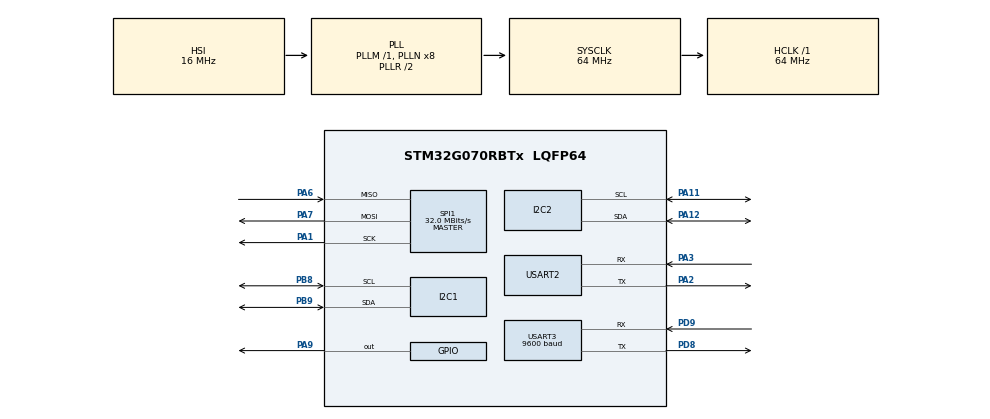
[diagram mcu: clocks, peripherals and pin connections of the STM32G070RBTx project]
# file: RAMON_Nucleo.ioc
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Dma.Request0=USART3_RX
Dma.USART3_RX.0.Direction=DMA_PERIPH_TO_MEMORY
Dma.USART3_RX.0.EventEnable=DISABLE
Dma.USART3_RX.0.Instance=DMA1_Channel1
Dma.USART3_RX.0.MemDataAlignment=DMA_MDATAALIGN_BYTE
Dma.USART3_RX.0.MemInc=DMA_MINC_ENABLE
Dma.USART3_RX.0.Mode=DMA_CIRCULAR
Dma.USART3_RX.0.PeriphDataAlignment=DMA_PDATAALIGN_BYTE
Dma.USART3_RX.0.PeriphInc=DMA_PINC_DISABLE
Dma.USART3_RX.0.Polarity=HAL_DMAMUX_REQ_GEN_RISING
Dma.USART3_RX.0.Priority=DMA_PRIORITY_LOW
Dma.USART3_RX.0.RequestNumber=1
Dma.USART3_RX.0.SignalID=NONE
Dma.USART3_RX.0.SyncEnable=DISABLE
Dma.USART3_RX.0.SyncPolarity=HAL_DMAMUX_SYNC_NO_EVENT
Dma.USART3_RX.0.SyncRequestNumber=1
Dma.USART3_RX.0.SyncSignalID=NONE
FATFS._MAX_SS=4096
FATFS._USE_LFN=1
I2C1.Timing=0x10707DBC
I2C2.Timing=0x10707DBC
Mcu.Family=STM32G0
Mcu.Name=STM32G070RBTx
Mcu.Package=LQFP64
NVIC.DMA1_Channel1_IRQn=true\:0\:0\:false\:false\:true\:false\:true\:true
PA1.Mode=Full_Duplex_Master
PA1.Signal=SPI1_SCK
PA11\ [PA9].Mode=I2C
PA11\ [PA9].Signal=I2C2_SCL
PA12\ [PA10].Mode=I2C
PA12\ [PA10].Signal=I2C2_SDA
PA13.GPIO_Label=TMS
PA13.Mode=Serial_Wire
PA13.Signal=SYS_SWDIO
PA14-BOOT0.GPIO_Label=TCK
PA14-BOOT0.Mode=Serial_Wire
PA14-BOOT0.Signal=SYS_SWCLK
PA2.GPIO_PuPd=GPIO_PULLUP
PA2.Mode=Asynchronous
PA2.Signal=USART2_TX
PA3.GPIO_PuPd=GPIO_PULLUP
PA3.Mode=Asynchronous
PA3.Signal=USART2_RX
PA6.Mode=Full_Duplex_Master
PA6.Signal=SPI1_MISO
PA7.Mode=Full_Duplex_Master
PA7.Signal=SPI1_MOSI
PA9.Signal=GPIO_Output
PB8.Mode=I2C
PB8.Signal=I2C1_SCL
PB9.Mode=I2C
PB9.Signal=I2C1_SDA
PC13.Mode=SYS_WakeUp1
PC13.Signal=SYS_WKUP2
PC14-OSC32_IN\ (PC14).Mode=LSE-External-Oscillator
PC14-OSC32_IN\ (PC14).Signal=RCC_OSC32_IN
PC15-OSC32_OUT\ (PC15).Mode=LSE-External-Oscillator
PC15-OSC32_OUT\ (PC15).Signal=RCC_OSC32_OUT
PD8.Mode=Asynchronous
PD8.Signal=USART3_TX
PD9.Mode=Asynchronous
PD9.Signal=USART3_RX
PF0-OSC_IN\ (PF0).GPIO_Label=MCO
PF0-OSC_IN\ (PF0).Mode=HSE-External-Oscillator
PF0-OSC_IN\ (PF0).Signal=RCC_OSC_IN
PF1-OSC_OUT\ (PF1).Mode=HSE-External-Oscillator
PF1-OSC_OUT\ (PF1).Signal=RCC_OSC_OUT
ProjectManager.HeapSize=0x200
ProjectManager.StackSize=0x400
ProjectManager.TargetToolchain=STM32CubeIDE
RCC.ADCFreq_Value=64000000
RCC.AHBFreq_Value=64000000
RCC.CortexFreq_Value=64000000
RCC.EXTERNAL_CLOCK_VALUE=12288000
RCC.HCLKFreq_Value=64000000
RCC.HSE_VALUE=8000000
RCC.HSI_VALUE=16000000
RCC.SYSCLKFreq_VALUE=64000000
RCC.SYSCLKSource=RCC_SYSCLKSOURCE_PLLCLK
RCC.VCOOutputFreq_Value=128000000
SPI1.CalculateBaudRate=32.0 MBits/s
SPI1.Direction=SPI_DIRECTION_2LINES
SPI1.Mode=SPI_MODE_MASTER
SPI1.VirtualType=VM_MASTER
USART2.VirtualMode-Asynchronous=VM_ASYNC
USART2.WordLength=WORDLENGTH_8B
USART3.BaudRate=9600
USART3.VirtualMode-Asynchronous=VM_ASYNC
VP_FATFS_VS_Generic.Mode=User_defined
VP_SYS_VS_DBSignals.Mode=DisableDeadBatterySignals
board=NUCLEO-G070RB

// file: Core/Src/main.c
/* USER CODE BEGIN Header */
/**
  ******************************************************************************
  * @file           : main.c
  * @brief          : Main program body
  ******************************************************************************
  * @attention
  *
  * Copyright (c) 2024 STMicroelectronics.
  * All rights reserved.
  *
  * This software is licensed under terms that can be found in the LICENSE file
  * in the root directory of this software component.
  * If no LICENSE file comes with this software, it is provided AS-IS.
  *
  ******************************************************************************
  */
/* USER CODE END Header */
#include "main.h"
#include "app_fatfs.h"

/* USER CODE BEGIN PTD */
#define USE_PSEUDO_SENSORS
/* USER CODE END PTD */

/* USER CODE BEGIN PD */
/*  SPI_HandleTypeDef hspi1;
                            FATFS fs;
                            FATFS *pfs;
                            FIL fil;
                            FRESULT fres;
                            DWORD fre_clust;
                            uint32_t totalSpace, freeSpace;
                            char buffer[100];
                            */
/* USER CODE END PD */

I2C_HandleTypeDef hi2c1;
I2C_HandleTypeDef hi2c2;

SPI_HandleTypeDef hspi1;

UART_HandleTypeDef huart2;
UART_HandleTypeDef huart3;
DMA_HandleTypeDef hdma_usart3_rx;

/* USER CODE BEGIN PV */

uint8_t rx_indx;
uint8_t rx_data[100];
uint8_t rx_buffer[100];
uint8_t transfer_cplt;

/* USER CODE END PV */

void SystemClock_Config(void);
static void MX_GPIO_Init(void);
static void MX_DMA_Init(void);
static void MX_USART2_UART_Init(void);
static void MX_I2C1_Init(void);
static void MX_I2C2_Init(void);
static void MX_SPI1_Init(void);
static void MX_USART3_UART_Init(void);

int main(void)
{

  /* MCU Configuration--------------------------------------------------------*/

  /* Reset of all peripherals, Initializes the Flash interface and the Systick. */
  HAL_Init();

  /* Configure the system clock */
  SystemClock_Config();

  /* Initialize all configured peripherals */
  MX_GPIO_Init();
  MX_DMA_Init();
  MX_USART2_UART_Init();
  if (MX_FATFS_Init() != APP_OK) {
    Error_Handler();
  }
  MX_I2C1_Init();
  MX_I2C2_Init();
  MX_SPI1_Init();
  MX_USART3_UART_Init();
  /* USER CODE BEGIN 2 */
  Start_UART_Reception(&huart2);
  if (PseudoSensor_Init(&huart2) != HAL_OK) {
      Error_Handler();
  }
  FlightSoftware_Init(&hi2c1, &hi2c2, &huart2);

  Debug_Print("Initialization complete. Starting main loop.\r\n");

  FlightSoftware_Run();
  /* USER CODE END 2 */

  /* Infinite loop */

}

void SystemClock_Config(void)
{
  RCC_OscInitTypeDef RCC_OscInitStruct = {0};
  RCC_ClkInitTypeDef RCC_ClkInitStruct = {0};

  /** Configure the main internal regulator output voltage
  */
  HAL_PWREx_ControlVoltageScaling(PWR_REGULATOR_VOLTAGE_SCALE1);

  /** Initializes the RCC Oscillators according to the specified parameters
  * in the RCC_OscInitTypeDef structure.
  */
  RCC_OscInitStruct.OscillatorType = RCC_OSCILLATORTYPE_HSI;
  RCC_OscInitStruct.HSIState = RCC_HSI_ON;
  RCC_OscInitStruct.HSIDiv = RCC_HSI_DIV1;
  RCC_OscInitStruct.HSICalibrationValue = RCC_HSICALIBRATION_DEFAULT;
  RCC_OscInitStruct.PLL.PLLState = RCC_PLL_ON;
  RCC_OscInitStruct.PLL.PLLSource = RCC_PLLSOURCE_HSI;
  RCC_OscInitStruct.PLL.PLLM = RCC_PLLM_DIV1;
  RCC_OscInitStruct.PLL.PLLN = 8;
  RCC_OscInitStruct.PLL.PLLP = RCC_PLLP_DIV2;
  RCC_OscInitStruct.PLL.PLLR = RCC_PLLR_DIV2;
  if (HAL_RCC_OscConfig(&RCC_OscInitStruct) != HAL_OK)
  {
    Error_Handler();
  }

  /** Initializes the CPU, AHB and APB buses clocks
  */
  RCC_ClkInitStruct.ClockType = RCC_CLOCKTYPE_HCLK|RCC_CLOCKTYPE_SYSCLK
                              |RCC_CLOCKTYPE_PCLK1;
  RCC_ClkInitStruct.SYSCLKSource = RCC_SYSCLKSOURCE_PLLCLK;
  RCC_ClkInitStruct.AHBCLKDivider = RCC_SYSCLK_DIV1;
  RCC_ClkInitStruct.APB1CLKDivider = RCC_HCLK_DIV1;

  if (HAL_RCC_ClockConfig(&RCC_ClkInitStruct, FLASH_LATENCY_2) != HAL_OK)
  {
    Error_Handler();
  }
}

static void MX_I2C1_Init(void)
{

  hi2c1.Instance = I2C1;
  hi2c1.Init.Timing = 0x10707DBC;
  hi2c1.Init.OwnAddress1 = 0;
  hi2c1.Init.AddressingMode = I2C_ADDRESSINGMODE_7BIT;
  hi2c1.Init.DualAddressMode = I2C_DUALADDRESS_DISABLE;
  hi2c1.Init.OwnAddress2 = 0;
  hi2c1.Init.OwnAddress2Masks = I2C_OA2_NOMASK;
  hi2c1.Init.GeneralCallMode = I2C_GENERALCALL_DISABLE;
  hi2c1.Init.NoStretchMode = I2C_NOSTRETCH_DISABLE;
  if (HAL_I2C_Init(&hi2c1) != HAL_OK)
  {
    Error_Handler();
  }

  /** Configure Analogue filter
  */
  if (HAL_I2CEx_ConfigAnalogFilter(&hi2c1, I2C_ANALOGFILTER_ENABLE) != HAL_OK)
  {
    Error_Handler();
  }

  /** Configure Digital filter
  */
  if (HAL_I2CEx_ConfigDigitalFilter(&hi2c1, 0) != HAL_OK)
  {
    Error_Handler();
  }

}

static void MX_I2C2_Init(void)
{

  hi2c2.Instance = I2C2;
  hi2c2.Init.Timing = 0x10707DBC;
  hi2c2.Init.OwnAddress1 = 0;
  hi2c2.Init.AddressingMode = I2C_ADDRESSINGMODE_7BIT;
  hi2c2.Init.DualAddressMode = I2C_DUALADDRESS_DISABLE;
  hi2c2.Init.OwnAddress2 = 0;
  hi2c2.Init.OwnAddress2Masks = I2C_OA2_NOMASK;
  hi2c2.Init.GeneralCallMode = I2C_GENERALCALL_DISABLE;
  hi2c2.Init.NoStretchMode = I2C_NOSTRETCH_DISABLE;
  if (HAL_I2C_Init(&hi2c2) != HAL_OK)
  {
    Error_Handler();
  }

  /** Configure Analogue filter
  */
  if (HAL_I2CEx_ConfigAnalogFilter(&hi2c2, I2C_ANALOGFILTER_ENABLE) != HAL_OK)
  {
    Error_Handler();
  }

  /** Configure Digital filter
  */
  if (HAL_I2CEx_ConfigDigitalFilter(&hi2c2, 0) != HAL_OK)
  {
    Error_Handler();
  }

}

static void MX_SPI1_Init(void)
{

  /* SPI1 parameter configuration*/
  hspi1.Instance = SPI1;
  hspi1.Init.Mode = SPI_MODE_MASTER;
  hspi1.Init.Direction = SPI_DIRECTION_2LINES;
  hspi1.Init.DataSize = SPI_DATASIZE_4BIT;
  hspi1.Init.CLKPolarity = SPI_POLARITY_LOW;
  hspi1.Init.CLKPhase = SPI_PHASE_1EDGE;
  hspi1.Init.NSS = SPI_NSS_SOFT;
  hspi1.Init.BaudRatePrescaler = SPI_BAUDRATEPRESCALER_2;
  hspi1.Init.FirstBit = SPI_FIRSTBIT_MSB;
  hspi1.Init.TIMode = SPI_TIMODE_DISABLE;
  hspi1.Init.CRCCalculation = SPI_CRCCALCULATION_DISABLE;
  hspi1.Init.CRCPolynomial = 7;
  hspi1.Init.CRCLength = SPI_CRC_LENGTH_DATASIZE;
  hspi1.Init.NSSPMode = SPI_NSS_PULSE_ENABLE;
  if (HAL_SPI_Init(&hspi1) != HAL_OK)
  {
    Error_Handler();
  }

}

static void MX_USART2_UART_Init(void)
{

  huart2.Instance = USART2;
  huart2.Init.BaudRate = 115200;
  huart2.Init.WordLength = UART_WORDLENGTH_8B;
  huart2.Init.StopBits = UART_STOPBITS_1;
  huart2.Init.Parity = UART_PARITY_NONE;
  huart2.Init.Mode = UART_MODE_TX_RX;
  huart2.Init.HwFlowCtl = UART_HWCONTROL_NONE;
  huart2.Init.OverSampling = UART_OVERSAMPLING_16;
  huart2.Init.OneBitSampling = UART_ONE_BIT_SAMPLE_DISABLE;
  huart2.Init.ClockPrescaler = UART_PRESCALER_DIV1;
  huart2.AdvancedInit.AdvFeatureInit = UART_ADVFEATURE_NO_INIT;
  if (HAL_UART_Init(&huart2) != HAL_OK)
  {
    Error_Handler();
  }
  if (HAL_UARTEx_SetTxFifoThreshold(&huart2, UART_TXFIFO_THRESHOLD_1_8) != HAL_OK)
  {
    Error_Handler();
  }
  if (HAL_UARTEx_SetRxFifoThreshold(&huart2, UART_RXFIFO_THRESHOLD_1_8) != HAL_OK)
  {
    Error_Handler();
  }
  if (HAL_UARTEx_DisableFifoMode(&huart2) != HAL_OK)
  {
    Error_Handler();
  }

}

static void MX_USART3_UART_Init(void)
{

  huart3.Instance = USART3;
  huart3.Init.BaudRate = 9600;
  huart3.Init.WordLength = UART_WORDLENGTH_8B;
  huart3.Init.StopBits = UART_STOPBITS_1;
  huart3.Init.Parity = UART_PARITY_NONE;
  huart3.Init.Mode = UART_MODE_TX_RX;
  huart3.Init.HwFlowCtl = UART_HWCONTROL_NONE;
  huart3.Init.OverSampling = UART_OVERSAMPLING_16;
  huart3.Init.OneBitSampling = UART_ONE_BIT_SAMPLE_DISABLE;
  huart3.Init.ClockPrescaler = UART_PRESCALER_DIV1;
  huart3.AdvancedInit.AdvFeatureInit = UART_ADVFEATURE_NO_INIT;
  if (HAL_UART_Init(&huart3) != HAL_OK)
  {
    Error_Handler();
  }

}

static void MX_DMA_Init(void)
{

  /* DMA controller clock enable */
  __HAL_RCC_DMA1_CLK_ENABLE();

  /* DMA interrupt init */
  /* DMA1_Channel1_IRQn interrupt configuration */
  HAL_NVIC_SetPriority(DMA1_Channel1_IRQn, 0, 0);
  HAL_NVIC_EnableIRQ(DMA1_Channel1_IRQn);

}

static void MX_GPIO_Init(void)
{
  GPIO_InitTypeDef GPIO_InitStruct = {0};

  /* GPIO Ports Clock Enable */
  __HAL_RCC_GPIOC_CLK_ENABLE();
  __HAL_RCC_GPIOF_CLK_ENABLE();
  __HAL_RCC_GPIOA_CLK_ENABLE();
  __HAL_RCC_GPIOD_CLK_ENABLE();
  __HAL_RCC_GPIOB_CLK_ENABLE();

  /*Configure GPIO pin Output Level */
  HAL_GPIO_WritePin(GPIOA, GPIO_PIN_9, GPIO_PIN_RESET);

  /*Configure GPIO pin : PA9 */
  GPIO_InitStruct.Pin = GPIO_PIN_9;
  GPIO_InitStruct.Mode = GPIO_MODE_OUTPUT_PP;
  GPIO_InitStruct.Pull = GPIO_NOPULL;
  GPIO_InitStruct.Speed = GPIO_SPEED_FREQ_LOW;
  HAL_GPIO_Init(GPIOA, &GPIO_InitStruct);

}

void Error_Handler(void)
{
  __disable_irq();
  while (1)
  {
  }
}
